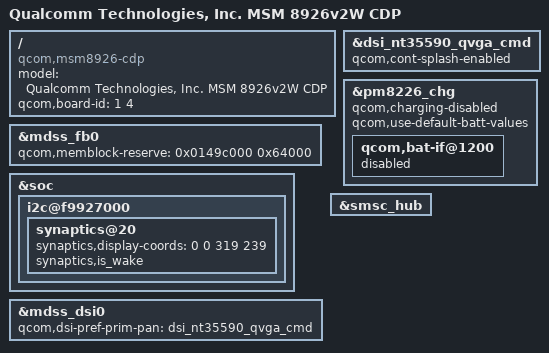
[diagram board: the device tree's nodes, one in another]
/* Copyright (c) 2015, The Linux Foundation. All rights reserved.
 *
 * This program is free software; you can redistribute it and/or modify
 * it under the terms of the GNU General Public License version 2 and
 * only version 2 as published by the Free Software Foundation.
 *
 * This program is distributed in the hope that it will be useful,
 * but WITHOUT ANY WARRANTY; without even the implied warranty of
 * MERCHANTABILITY or FITNESS FOR A PARTICULAR PURPOSE.  See the
 * GNU General Public License for more details.
 */

/dts-v1/;
/include/ "msm8926-v2.dtsi"
/include/ "msm8926-w-memory.dtsi"
/include/ "msm8926-w-ion.dtsi"
/include/ "msm8926-w-qseecom.dtsi"
/include/ "msm8926-w-sharedmem.dtsi"
/include/ "msm8226-720p-cdp.dtsi"
/include/ "msm8226-camera-sensor-mtp.dtsi"
/include/ "msm8x26w-gpu.dtsi"

/ {
	model = "Qualcomm Technologies, Inc. MSM 8926v2W CDP";
	compatible = "qcom,msm8926-cdp", "qcom,msm8926", "qcom,cdp";
	qcom,board-id = <1 4>;
};

&mdss_fb0 {
	/* cont_splash memory*/
	qcom,memblock-reserve = <0x0149c000 0x64000>;
};

&soc {
	i2c@f9927000 { /* BLSP1 QUP5 */
		synaptics@20 {
			synaptics,display-coords = <0 0 319 239>;
			/delete-property/ synaptics,power-down;
			/delete-property/ synaptics,disable-gpios;
			synaptics,is_wake;
		};
	};
};

&mdss_dsi0 {
	qcom,dsi-pref-prim-pan = <&dsi_nt35590_qvga_cmd>;
};

&dsi_nt35590_qvga_cmd {
	qcom,cont-splash-enabled;
};

&pm8226_chg {
	status = "ok";
	qcom,charging-disabled;
	qcom,use-default-batt-values;

	qcom,bat-if@1200 {
		status = "disabled";
	};

};

&smsc_hub {
	status = "ok";
};
